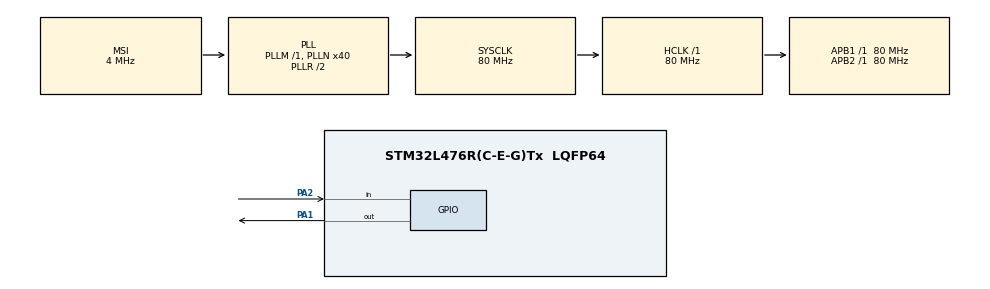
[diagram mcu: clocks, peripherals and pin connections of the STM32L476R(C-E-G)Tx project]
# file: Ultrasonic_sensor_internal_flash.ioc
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Mcu.Family=STM32L4
Mcu.Name=STM32L476R(C-E-G)Tx
Mcu.Package=LQFP64
NVIC.PriorityGroup=NVIC_PRIORITYGROUP_4
PA1.Signal=GPIO_Output
PA2.Signal=GPIO_Input
ProjectManager.HeapSize=0x200
ProjectManager.StackSize=0x400
ProjectManager.TargetToolchain=STM32CubeIDE
RCC.AHBFreq_Value=80000000
RCC.APB1Freq_Value=80000000
RCC.APB1TimFreq_Value=80000000
RCC.APB2Freq_Value=80000000
RCC.APB2TimFreq_Value=80000000
RCC.CortexFreq_Value=80000000
RCC.HCLKFreq_Value=80000000
RCC.HSE_VALUE=8000000
RCC.HSI_VALUE=16000000
RCC.LSE_VALUE=32768
RCC.MSI_VALUE=4000000
RCC.PLLN=40
RCC.SYSCLKFreq_VALUE=80000000
RCC.SYSCLKSource=RCC_SYSCLKSOURCE_PLLCLK
RCC.VCOOutputFreq_Value=160000000
TIM2.Prescaler=79
VP_TIM2_VS_ClockSourceINT.Mode=Internal
board=custom

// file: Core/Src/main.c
/* USER CODE BEGIN Header */
/**
 ******************************************************************************
 * @file           : main.c
 * @brief          : Main program body
 ******************************************************************************
 * @attention
 *
 * Copyright (c) 2025 STMicroelectronics.
 * All rights reserved.
 *
 * This software is licensed under terms that can be found in the LICENSE file
 * in the root directory of this software component.
 * If no LICENSE file comes with this software, it is provided AS-IS.
 *
 ******************************************************************************
 */
/* USER CODE END Header */
#include "main.h"

/* USER CODE BEGIN PD */
#define TRIG_PIN 1
#define ECHO_PIN 2
#define FLASH_ADDR  0x0807F800  // last page of 1MB Flash (adjust if smaller device)
/* USER CODE END PD */

TIM_HandleTypeDef htim2;

void SystemClock_Config(void);
static void MX_GPIO_Init(void);
static void MX_TIM2_Init(void);

/* USER CODE BEGIN 0 */
void delay_us(uint32_t us)
{
	TIM2->CNT = 0;
	while (TIM2->CNT < us);
}

void TIM2_Init(void)
{
	RCC->APB1ENR1 |= RCC_APB1ENR1_TIM2EN;
	TIM2->PSC = 16 - 1;      // 1 MHz tick (1 µs)
	TIM2->ARR = 0xFFFF;
	TIM2->CR1 |= TIM_CR1_CEN;
}

void GPIO_Init(void)
{
	RCC->AHB2ENR |= RCC_AHB2ENR_GPIOAEN;
	GPIOA->MODER &= ~((3U << (TRIG_PIN*2)) | (3U << (ECHO_PIN*2)));
	GPIOA->MODER |= (1U << (TRIG_PIN*2));    // PA1 output
}

uint32_t Measure_Distance(void)
{
	uint32_t start, end, timeout;

	GPIOA->ODR &= ~(1U << TRIG_PIN);
	delay_us(2);
	GPIOA->ODR |= (1U << TRIG_PIN);
	delay_us(10);
	GPIOA->ODR &= ~(1U << TRIG_PIN);

	timeout = 60000;
	while (!(GPIOA->IDR & (1U << ECHO_PIN))) {
		if (--timeout == 0) return 0;
	}

	start = TIM2->CNT;
	while (GPIOA->IDR & (1U << ECHO_PIN)) {
		if ((TIM2->CNT - start) > 60000) return 0;
	}
	end = TIM2->CNT;

	uint32_t pulse_width = (end >= start) ? (end - start) : (0xFFFF - start + end);
	return pulse_width / 58; // cm
}

#include "stm32l476xx.h"

void Flash_Write(uint32_t address, uint64_t data)
{
	// 1. Unlock flash
	if (FLASH->CR & FLASH_CR_LOCK) {
		FLASH->KEYR = 0x45670123;
		FLASH->KEYR = 0xCDEF89AB;
	}

	// 2. Wait if busy
	while (FLASH->SR & FLASH_SR_BSY);

	// 3. Enable programming
	FLASH->CR |= FLASH_CR_PG;

	// 4. Write 64-bit data (STM32L4 flash programming granularity is 64-bit)
	*(__IO uint64_t *)address = data;

	// 5. Wait until done
	while (FLASH->SR & FLASH_SR_BSY);

	// 6. Disable programming
	FLASH->CR &= ~FLASH_CR_PG;

	// 7. Lock flash
	FLASH->CR |= FLASH_CR_LOCK;
}

/* USER CODE END 0 */

int main(void)
{

	/* MCU Configuration--------------------------------------------------------*/

	/* Reset of all peripherals, Initializes the Flash interface and the Systick. */
	HAL_Init();

	/* Configure the system clock */
	SystemClock_Config();

	/* Initialize all configured peripherals */
	MX_GPIO_Init();
	MX_TIM2_Init();
	/* USER CODE BEGIN 2 */
	HAL_TIM_Base_Start(&htim2);
	uint32_t distance;
	/* USER CODE END 2 */

	/* Infinite loop */
	while (1)
	{

		/* USER CODE BEGIN 3 */
		distance = Measure_Distance();
		Flash_Write(FLASH_ADDR, distance);
		for (volatile uint32_t i=0; i<1000000; i++);
	}
	/* USER CODE END 3 */
}

void SystemClock_Config(void)
{
	RCC_OscInitTypeDef RCC_OscInitStruct = {0};
	RCC_ClkInitTypeDef RCC_ClkInitStruct = {0};

	/** Configure the main internal regulator output voltage
	 */
	if (HAL_PWREx_ControlVoltageScaling(PWR_REGULATOR_VOLTAGE_SCALE1) != HAL_OK)
	{
		Error_Handler();
	}

	/** Initializes the RCC Oscillators according to the specified parameters
	 * in the RCC_OscInitTypeDef structure.
	 */
	RCC_OscInitStruct.OscillatorType = RCC_OSCILLATORTYPE_MSI;
	RCC_OscInitStruct.MSIState = RCC_MSI_ON;
	RCC_OscInitStruct.MSICalibrationValue = 0;
	RCC_OscInitStruct.MSIClockRange = RCC_MSIRANGE_6;
	RCC_OscInitStruct.PLL.PLLState = RCC_PLL_ON;
	RCC_OscInitStruct.PLL.PLLSource = RCC_PLLSOURCE_MSI;
	RCC_OscInitStruct.PLL.PLLM = 1;
	RCC_OscInitStruct.PLL.PLLN = 40;
	RCC_OscInitStruct.PLL.PLLP = RCC_PLLP_DIV7;
	RCC_OscInitStruct.PLL.PLLQ = RCC_PLLQ_DIV2;
	RCC_OscInitStruct.PLL.PLLR = RCC_PLLR_DIV2;
	if (HAL_RCC_OscConfig(&RCC_OscInitStruct) != HAL_OK)
	{
		Error_Handler();
	}

	/** Initializes the CPU, AHB and APB buses clocks
	 */
	RCC_ClkInitStruct.ClockType = RCC_CLOCKTYPE_HCLK|RCC_CLOCKTYPE_SYSCLK
			|RCC_CLOCKTYPE_PCLK1|RCC_CLOCKTYPE_PCLK2;
	RCC_ClkInitStruct.SYSCLKSource = RCC_SYSCLKSOURCE_PLLCLK;
	RCC_ClkInitStruct.AHBCLKDivider = RCC_SYSCLK_DIV1;
	RCC_ClkInitStruct.APB1CLKDivider = RCC_HCLK_DIV1;
	RCC_ClkInitStruct.APB2CLKDivider = RCC_HCLK_DIV1;

	if (HAL_RCC_ClockConfig(&RCC_ClkInitStruct, FLASH_LATENCY_4) != HAL_OK)
	{
		Error_Handler();
	}
}

static void MX_TIM2_Init(void)
{

	TIM_ClockConfigTypeDef sClockSourceConfig = {0};
	TIM_MasterConfigTypeDef sMasterConfig = {0};

	htim2.Instance = TIM2;
	htim2.Init.Prescaler = 79;
	htim2.Init.CounterMode = TIM_COUNTERMODE_UP;
	htim2.Init.Period = 4294967295;
	htim2.Init.ClockDivision = TIM_CLOCKDIVISION_DIV1;
	htim2.Init.AutoReloadPreload = TIM_AUTORELOAD_PRELOAD_DISABLE;
	if (HAL_TIM_Base_Init(&htim2) != HAL_OK)
	{
		Error_Handler();
	}
	sClockSourceConfig.ClockSource = TIM_CLOCKSOURCE_INTERNAL;
	if (HAL_TIM_ConfigClockSource(&htim2, &sClockSourceConfig) != HAL_OK)
	{
		Error_Handler();
	}
	sMasterConfig.MasterOutputTrigger = TIM_TRGO_RESET;
	sMasterConfig.MasterSlaveMode = TIM_MASTERSLAVEMODE_DISABLE;
	if (HAL_TIMEx_MasterConfigSynchronization(&htim2, &sMasterConfig) != HAL_OK)
	{
		Error_Handler();
	}

}

static void MX_GPIO_Init(void)
{
	GPIO_InitTypeDef GPIO_InitStruct = {0};

	/* GPIO Ports Clock Enable */
	__HAL_RCC_GPIOA_CLK_ENABLE();

	/*Configure GPIO pin Output Level */
	HAL_GPIO_WritePin(GPIOA, GPIO_PIN_1, GPIO_PIN_RESET);

	/*Configure GPIO pin : PA1 */
	GPIO_InitStruct.Pin = GPIO_PIN_1;
	GPIO_InitStruct.Mode = GPIO_MODE_OUTPUT_PP;
	GPIO_InitStruct.Pull = GPIO_NOPULL;
	GPIO_InitStruct.Speed = GPIO_SPEED_FREQ_LOW;
	HAL_GPIO_Init(GPIOA, &GPIO_InitStruct);

	/*Configure GPIO pin : PA2 */
	GPIO_InitStruct.Pin = GPIO_PIN_2;
	GPIO_InitStruct.Mode = GPIO_MODE_INPUT;
	GPIO_InitStruct.Pull = GPIO_NOPULL;
	HAL_GPIO_Init(GPIOA, &GPIO_InitStruct);

}

void Error_Handler(void)
{
	__disable_irq();
	while (1)
	{
	}
}
